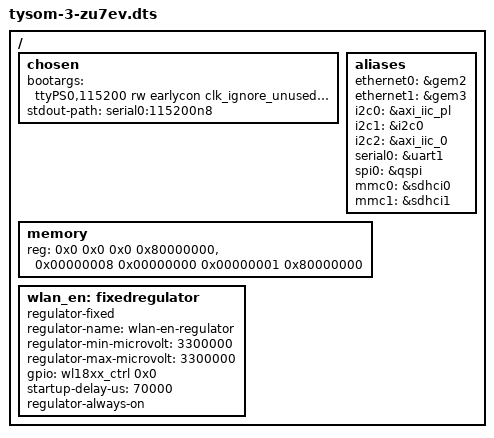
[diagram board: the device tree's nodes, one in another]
/*
 * CAUTION: This file is automatically generated by Xilinx.
 * Version: XSCT 2018.3
 * Today is: Fri Feb  1 12:27:28 2019
 */


/dts-v1/;
/include/ "zynqmp.dtsi"
/include/ "zynqmp-clk-ccf.dtsi"
/include/ "pl.dtsi"
/include/ "pcw.dtsi"
/ {
	chosen {
		bootargs = "ttyPS0,115200 rw earlycon clk_ignore_unused root=/dev/ram0 earlyprintk uio_pdrv_genirq.of_id=xlnx,generic-uio cma=1024M";
		stdout-path = "serial0:115200n8";
	};
	aliases {
		ethernet0 = &gem2;
		ethernet1 = &gem3;
		i2c0 = &axi_iic_pl;
		i2c1 = &i2c0;
		i2c2 = &axi_iic_0;
		serial0 = &uart1;
		spi0 = &qspi;
		mmc0 = &sdhci0;
		mmc1 = &sdhci1;
	};
	memory {
		device_type = "memory";
		reg = <0x0 0x0 0x0 0x80000000>, <0x00000008 0x00000000 0x00000001 0x80000000>;
	};
	
	wlan_en: fixedregulator {
		compatible = "regulator-fixed";
		regulator-name = "wlan-en-regulator";
		regulator-min-microvolt = <3300000>;
		regulator-max-microvolt = <3300000>;
		gpio = <&wl18xx_ctrl 0x0 0x0>;
		startup-delay-us = <70000>;
		regulator-always-on;
	};
};
